CM_ "AUTOGENERATED FILE, DO NOT EDIT";

CM_ "Imported file _stellantis_common.dbc starts here";
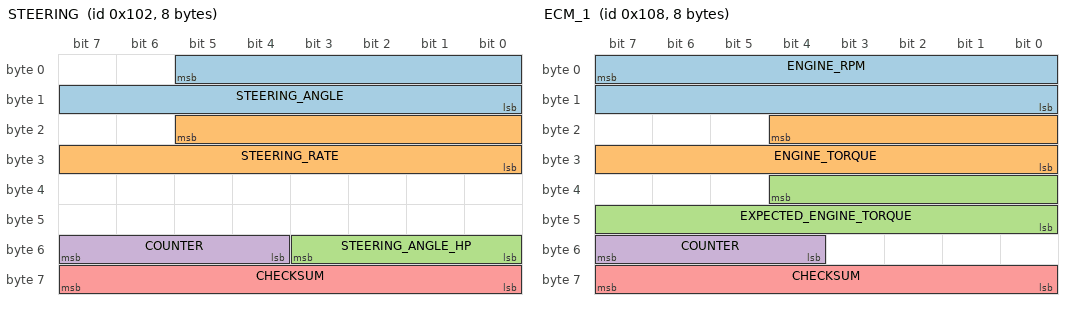
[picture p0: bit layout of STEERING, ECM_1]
BO_ 258 STEERING: 8 XXX
 SG_ STEERING_ANGLE : 5|14@0+ (0.5,-2048) [-2048|2047] "deg" XXX
 SG_ STEERING_RATE : 21|14@0+ (0.5,-2048) [-2048|2047] "deg/s" XXX
 SG_ STEERING_ANGLE_HP : 48|4@1+ (0.1,-0.4) [-0.4|0.4] "deg" XXX
 SG_ COUNTER : 55|4@0+ (1,0) [0|15] "" XXX
 SG_ CHECKSUM : 63|8@0+ (1,0) [0|255] "" XXX

BO_ 264 ECM_1: 8 XXX
 SG_ ENGINE_RPM : 7|16@0+ (1,0) [0|65535] "" XXX
 SG_ ENGINE_TORQUE : 20|13@0+ (0.25,-500) [-500|1547.5] "Nm" XXX
 SG_ EXPECTED_ENGINE_TORQUE : 36|13@0+ (0.25,-500) [-500|1547.5] "Nm" XXX
 SG_ COUNTER : 55|4@0+ (1,0) [0|15] "" XXX
 SG_ CHECKSUM : 63|8@0+ (1,0) [0|255] "" XXX

BO_ 280 ECM_TRQ: 8 XXX
 SG_ ENGINE_TORQ_MAX : 4|13@0+ (.25,-500) [-500|1547.5] "NM" XXX
 SG_ ENGINE_TORQ_MIN : 20|13@0+ (.25,-500) [-500|1547.5] "NM" XXX

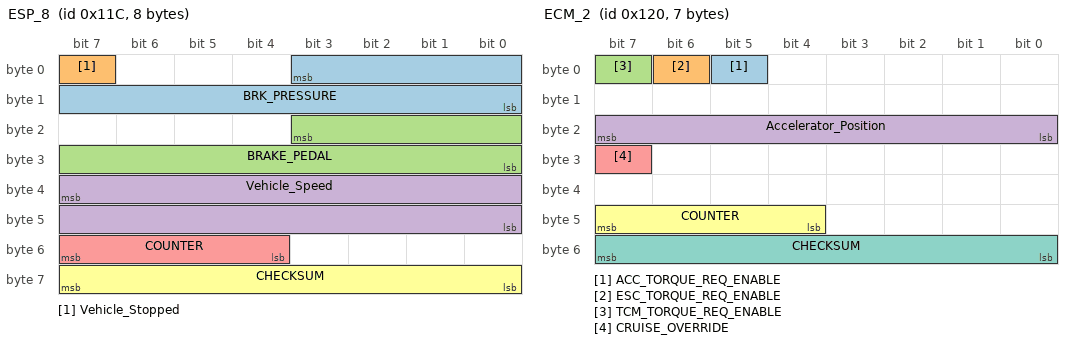
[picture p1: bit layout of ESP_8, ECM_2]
BO_ 284 ESP_8: 8 XXX
 SG_ BRK_PRESSURE : 3|12@0+ (1,0) [0|1] "" XXX
 SG_ Vehicle_Stopped : 7|1@0+ (1,0) [0|1] "" XXX
 SG_ BRAKE_PEDAL : 19|12@0+ (1,0) [0|1] "" XXX
 SG_ Vehicle_Speed : 39|16@0+ (0.0078125,0) [0|511.984375] "km/h" XXX
 SG_ COUNTER : 55|4@0+ (1,0) [0|15] "" XXX
 SG_ CHECKSUM : 63|8@0+ (1,0) [0|255] "" XXX

BO_ 288 ECM_2: 7 XXX
 SG_ ACC_TORQUE_REQ_ENABLE : 5|1@1+ (1,0) [0|0] "" XXX
 SG_ ESC_TORQUE_REQ_ENABLE : 6|1@1+ (1,0) [0|0] "" XXX
 SG_ TCM_TORQUE_REQ_ENABLE : 7|1@1+ (1,0) [0|0] "" XXX
 SG_ Accelerator_Position : 16|8@1+ (0.4,0) [0|100] "%" XXX
 SG_ CRUISE_OVERRIDE : 31|1@1+ (1,0) [0|0] "" XXX
 SG_ COUNTER : 47|4@0+ (1,0) [0|15] "" XXX
 SG_ CHECKSUM : 55|8@0+ (1,0) [0|0] "" XXX

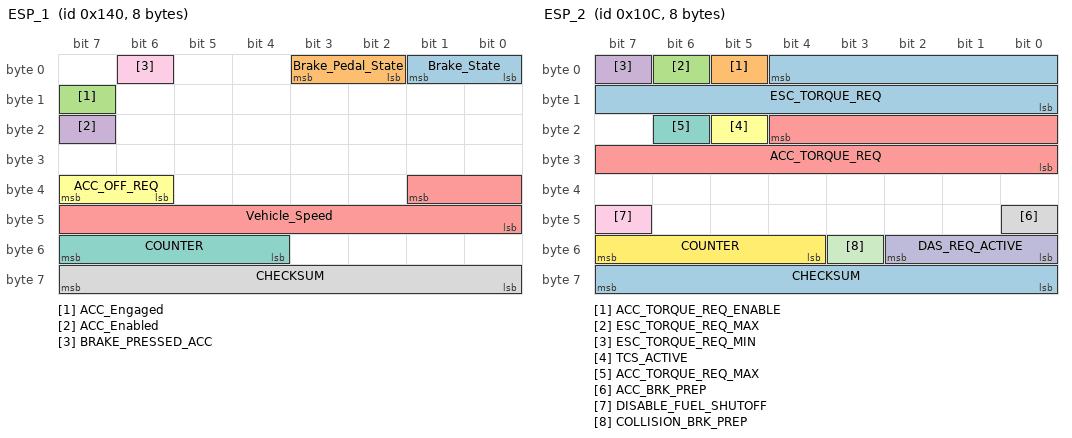
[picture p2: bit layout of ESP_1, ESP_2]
BO_ 320 ESP_1: 8 XXX
 SG_ Brake_State : 0|2@1+ (1,0) [0|0] "" XXX
 SG_ Brake_Pedal_State : 2|2@1+ (1,0) [0|0] "" XXX
 SG_ ACC_Engaged : 15|1@0+ (1,0) [0|1] "" XXX
 SG_ ACC_Enabled : 23|1@0+ (1,0) [0|1] "" XXX
 SG_ Vehicle_Speed : 33|10@0+ (0.5,0) [0|511] "km/h" XXX
 SG_ ACC_OFF_REQ : 39|2@0+ (1,0) [0|0] "" XXX
 SG_ COUNTER : 55|4@0+ (1,0) [0|15] "" XXX
 SG_ CHECKSUM : 63|8@0+ (1,0) [0|255] "" XXX
 SG_ BRAKE_PRESSED_ACC : 6|1@0+ (1,0) [0|3] "" XXX

BO_ 268 ESP_2: 8 ESC
 SG_ ESC_TORQUE_REQ : 4|13@0+ (0.25,-500) [-500|1547.5] "Nm" XXX
 SG_ ACC_TORQUE_REQ_ENABLE : 5|1@1+ (1,0) [0|0] "" XXX
 SG_ ESC_TORQUE_REQ_MAX : 6|1@1+ (1,0) [0|0] "" XXX
 SG_ ESC_TORQUE_REQ_MIN : 7|1@1+ (1,0) [0|0] "" XXX
 SG_ ACC_TORQUE_REQ : 20|13@0+ (0.25,-500) [-500|1547.5] "Nm" XXX
 SG_ TCS_ACTIVE : 21|1@1+ (1,0) [0|0] "" XXX
 SG_ ACC_TORQUE_REQ_MAX : 22|1@1+ (1,0) [0|0] "" XXX
 SG_ ACC_BRK_PREP : 40|1@1+ (1,0) [0|0] "" XXX
 SG_ DISABLE_FUEL_SHUTOFF : 47|1@1+ (1,0) [0|0] "" XXX
 SG_ DAS_REQ_ACTIVE : 48|3@1+ (1,0) [0|0] "" XXX
 SG_ COLLISION_BRK_PREP : 51|1@1+ (1,0) [0|0] "" XXX
 SG_ COUNTER : 55|4@0+ (1,0) [0|15] "" XXX
 SG_ CHECKSUM : 63|8@0+ (1,0) [0|0] "" XXX

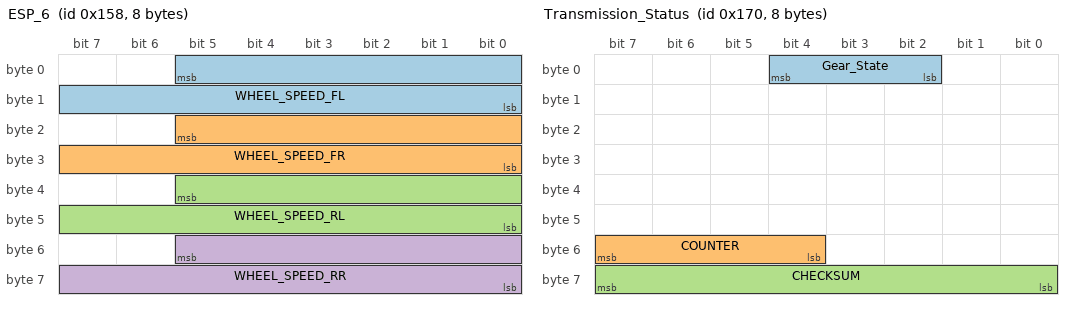
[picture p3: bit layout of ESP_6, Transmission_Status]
BO_ 344 ESP_6: 8 XXX
 SG_ WHEEL_SPEED_FL : 5|14@0+ (0.5,0) [0|8191] "rpm" XXX
 SG_ WHEEL_SPEED_FR : 21|14@0+ (0.5,0) [0|8191] "rpm" XXX
 SG_ WHEEL_SPEED_RL : 37|14@0+ (0.5,0) [0|8191] "rpm" XXX
 SG_ WHEEL_SPEED_RR : 53|14@0+ (0.5,0) [0|8191] "rpm" XXX

BO_ 368 Transmission_Status: 8 XXX
 SG_ Gear_State : 2|3@1+ (1,0) [0|15] "" XXX
 SG_ COUNTER : 55|4@0+ (1,0) [0|15] "" XXX
 SG_ CHECKSUM : 63|8@0+ (1,0) [0|255] "" XXX

BO_ 464 ORC_1: 8 XXX
 SG_ SEATBELT_DRIVER_UNLATCHED : 13|1@0+ (1,0) [0|1] "" XXX

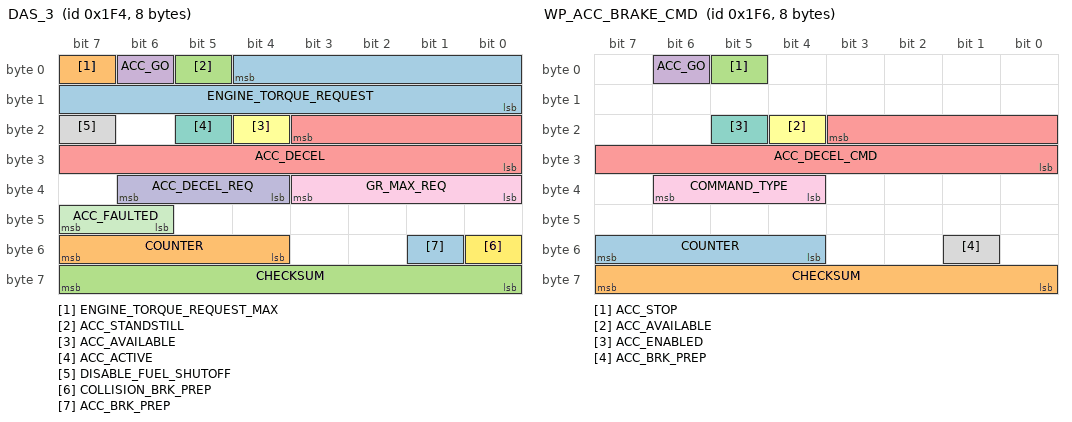
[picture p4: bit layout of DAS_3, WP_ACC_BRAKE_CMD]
BO_ 500 DAS_3: 8 XXX
 SG_ ENGINE_TORQUE_REQUEST : 4|13@0+ (0.25,-500) [-500|1547.5] "Nm" XXX
 SG_ ENGINE_TORQUE_REQUEST_MAX : 7|1@0+ (1,0) [0|1] "" XXX
 SG_ ACC_STANDSTILL : 5|1@0+ (1,0) [0|1] ""  XXX
 SG_ ACC_GO : 6|1@1+ (1,0) [0|0] "" XXX
 SG_ ACC_DECEL : 19|12@0+ (0.004885,-16) [-16|4] "m/s2" XXX
 SG_ ACC_AVAILABLE : 20|1@0+ (1,0) [0|1] "" XXX
 SG_ ACC_ACTIVE : 21|1@0+ (1,0) [0|1] "" XXX
 SG_ DISABLE_FUEL_SHUTOFF : 23|1@1+ (1,0) [0|0] "" XXX
 SG_ GR_MAX_REQ : 32|4@1+ (1,0) [0|0] "" XXX
 SG_ ACC_DECEL_REQ : 36|3@1+ (1,0) [0|0] "" XXX
 SG_ ACC_FAULTED : 46|2@1+ (1,0) [0|0] "" XXX
 SG_ COLLISION_BRK_PREP : 48|1@1+ (1,0) [0|0] "" XXX
 SG_ ACC_BRK_PREP : 49|1@1+ (1,0) [0|0] "" XXX
 SG_ COUNTER : 55|4@0+ (1,0) [0|15] "" XXX
 SG_ CHECKSUM : 63|8@0+ (1,0) [0|255] "" XXX

BO_ 502 WP_ACC_BRAKE_CMD: 8 XXX
 SG_ COUNTER : 55|4@0+ (1,0) [0|15] "" XXX
 SG_ CHECKSUM : 63|8@0+ (1,0) [0|255] "" XXX
 SG_ ACC_STOP : 5|1@0+ (1,0) [0|1] "" XXX
 SG_ ACC_GO : 6|1@0+ (1,0) [0|1] "" XXX
 SG_ ACC_DECEL_CMD : 19|12@0+ (0.004885,-16) [-16|4] "m/s2" XXX
 SG_ ACC_AVAILABLE : 20|1@0+ (1,0) [0|1] "" XXX
 SG_ ACC_ENABLED : 21|1@0+ (1,0) [0|1] "" XXX
 SG_ ACC_BRK_PREP : 49|1@0+ (1,0) [0|1] "" XXX
 SG_ COMMAND_TYPE : 38|3@0+ (1,0) [0|7] "" XXX

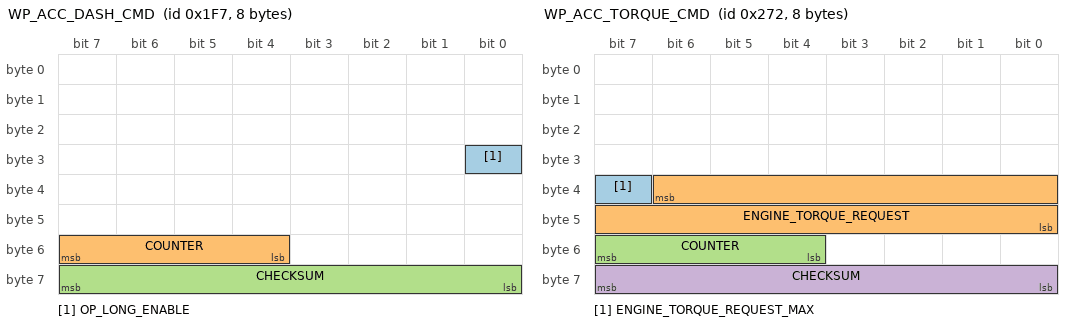
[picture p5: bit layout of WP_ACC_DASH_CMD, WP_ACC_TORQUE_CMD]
BO_ 503 WP_ACC_DASH_CMD: 8 XXX
 SG_ OP_LONG_ENABLE : 24|1@0+ (1,0) [0|1] "" XXX
 SG_ COUNTER : 55|4@0+ (1,0) [0|15] "" XXX
 SG_ CHECKSUM : 63|8@0+ (1,0) [0|255] "" XXX

BO_ 626 WP_ACC_TORQUE_CMD: 8 XXX
 SG_ ENGINE_TORQUE_REQUEST_MAX : 39|1@0+ (1,0) [0|1] "" XXX
 SG_ ENGINE_TORQUE_REQUEST : 38|15@0+ (0.25,-500) [-500|1547.5] "Nm" XXX
 SG_ COUNTER : 55|4@0+ (1,0) [0|15] "" XXX
 SG_ CHECKSUM : 63|8@0+ (1,0) [0|255] "" XXX

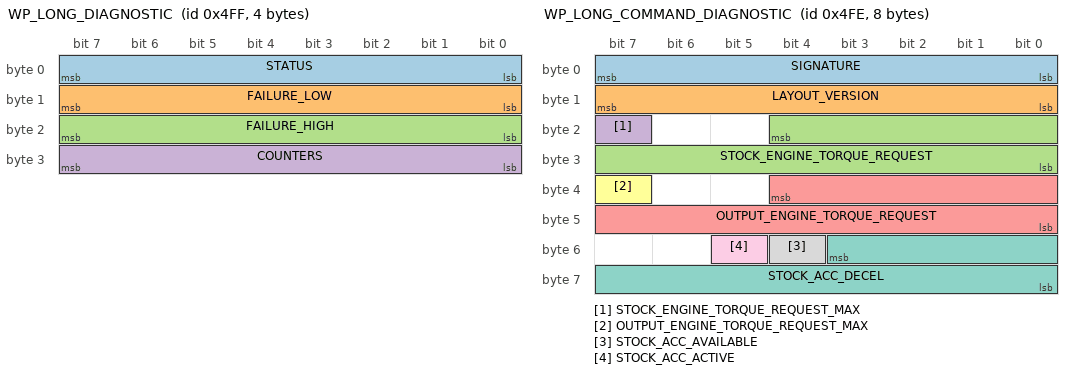
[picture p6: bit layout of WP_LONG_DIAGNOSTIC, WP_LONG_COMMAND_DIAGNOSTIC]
BO_ 1279 WP_LONG_DIAGNOSTIC: 4 XXX
 SG_ STATUS : 7|8@0+ (1,0) [0|255] "" XXX
 SG_ FAILURE_LOW : 15|8@0+ (1,0) [0|255] "" XXX
 SG_ FAILURE_HIGH : 23|8@0+ (1,0) [0|255] "" XXX
 SG_ COUNTERS : 31|8@0+ (1,0) [0|255] "" XXX

BO_ 1278 WP_LONG_COMMAND_DIAGNOSTIC: 8 XXX
 SG_ SIGNATURE : 7|8@0+ (1,0) [0|255] "" XXX
 SG_ LAYOUT_VERSION : 15|8@0+ (1,0) [0|255] "" XXX
 SG_ STOCK_ENGINE_TORQUE_REQUEST : 20|13@0+ (0.25,-500) [-500|1547.5] "Nm" XXX
 SG_ STOCK_ENGINE_TORQUE_REQUEST_MAX : 23|1@0+ (1,0) [0|1] "" XXX
 SG_ OUTPUT_ENGINE_TORQUE_REQUEST : 36|13@0+ (0.25,-500) [-500|1547.5] "Nm" XXX
 SG_ OUTPUT_ENGINE_TORQUE_REQUEST_MAX : 39|1@0+ (1,0) [0|1] "" XXX
 SG_ STOCK_ACC_DECEL : 51|12@0+ (0.004885,-16) [-16|4] "m/s2" XXX
 SG_ STOCK_ACC_AVAILABLE : 52|1@0+ (1,0) [0|1] "" XXX
 SG_ STOCK_ACC_ACTIVE : 53|1@0+ (1,0) [0|1] "" XXX

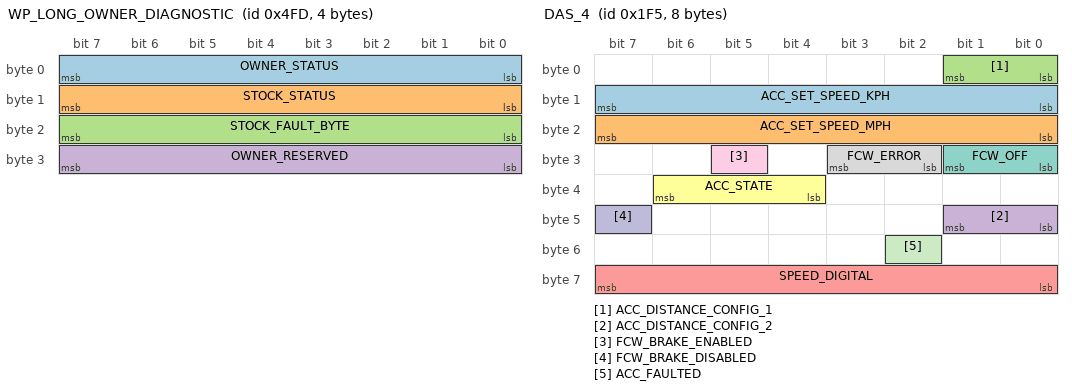
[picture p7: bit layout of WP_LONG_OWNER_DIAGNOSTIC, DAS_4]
BO_ 1277 WP_LONG_OWNER_DIAGNOSTIC: 4 XXX
 SG_ OWNER_STATUS : 7|8@0+ (1,0) [0|255] "" XXX
 SG_ STOCK_STATUS : 15|8@0+ (1,0) [0|255] "" XXX
 SG_ STOCK_FAULT_BYTE : 23|8@0+ (1,0) [0|255] "" XXX
 SG_ OWNER_RESERVED : 31|8@0+ (1,0) [0|255] "" XXX

BO_ 501 DAS_4: 8 XXX
 SG_ ACC_SET_SPEED_KPH : 15|8@0+ (1,0) [0|3] "km/h" XXX
 SG_ ACC_SET_SPEED_MPH : 23|8@0+ (1,0) [0|3] "mph" XXX
 SG_ ACC_DISTANCE_CONFIG_1 : 1|2@0+ (1,0) [0|3] "" XXX
 SG_ ACC_DISTANCE_CONFIG_2 : 41|2@0+ (1,0) [0|3] "" XXX
 SG_ SPEED_DIGITAL : 63|8@0+ (1,0) [0|255] "mph" XXX
 SG_ ACC_STATE : 38|3@0+ (1,0) [0|7] "" XXX
 SG_ FCW_OFF : 25|2@0+ (1,0) [0|3] "" XXX
 SG_ FCW_ERROR : 27|2@0+ (1,0) [0|3] "" XXX
 SG_ FCW_BRAKE_ENABLED : 29|1@0+ (1,0) [0|1] "" XXX
 SG_ FCW_BRAKE_DISABLED : 47|1@0+ (1,0) [0|1] "" XXX
 SG_ ACC_FAULTED : 50|1@0+ (1,0) [0|1] "" XXX

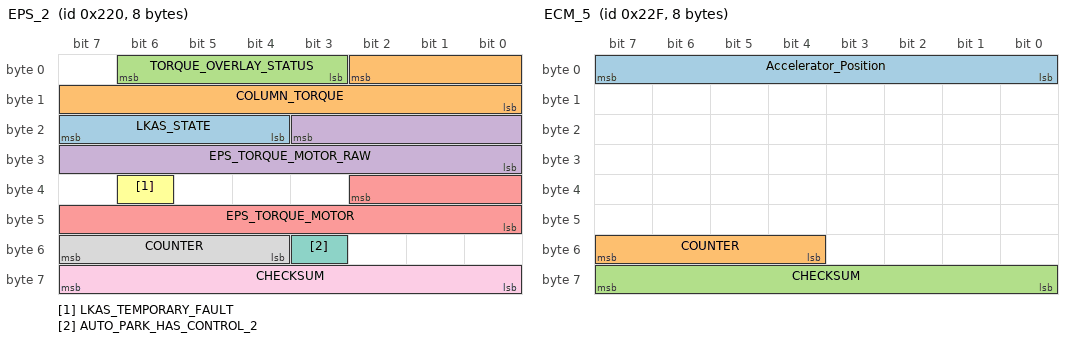
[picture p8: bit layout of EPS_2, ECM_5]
BO_ 544 EPS_2: 8 XXX
 SG_ LKAS_STATE : 23|4@0+ (1,0) [0|15] "" XXX
 SG_ COLUMN_TORQUE : 2|11@0+ (1,-1024) [-1024|1023] "" XXX
 SG_ TORQUE_OVERLAY_STATUS : 6|4@0+ (1,0) [0|15] "" XXX
 SG_ EPS_TORQUE_MOTOR_RAW : 19|12@0+ (1,-2048) [-2048|2047] "" XXX
 SG_ EPS_TORQUE_MOTOR : 34|11@0+ (1,-1024) [-1024|1023] "" XXX
 SG_ LKAS_TEMPORARY_FAULT : 38|1@0+ (1,0) [0|1] "" XXX
 SG_ AUTO_PARK_HAS_CONTROL_2 : 51|1@0+ (1,0) [0|1] "" XXX
 SG_ COUNTER : 55|4@0+ (1,0) [0|15] "" XXX
 SG_ CHECKSUM : 63|8@0+ (1,0) [0|255] "" XXX

BO_ 559 ECM_5: 8 XXX
 SG_ Accelerator_Position : 0|8@1+ (0.4,0) [0|100] "%" XXX
 SG_ COUNTER : 55|4@0+ (1,0) [0|15] "" XXX
 SG_ CHECKSUM : 63|8@0+ (1,0) [0|255] "" XXX

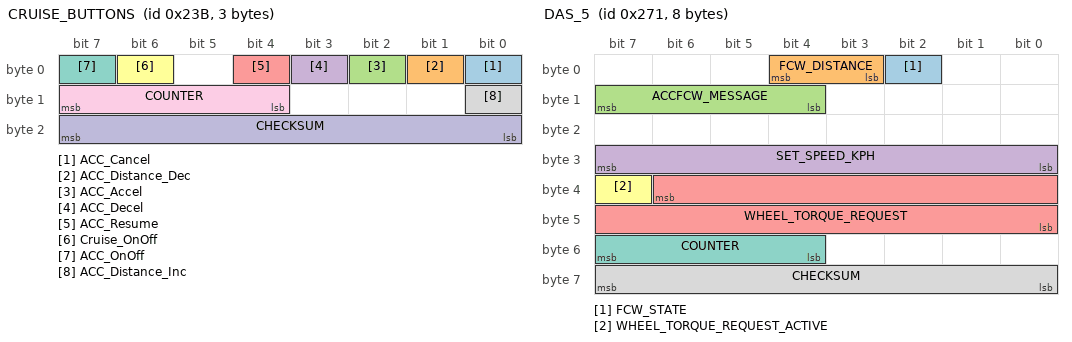
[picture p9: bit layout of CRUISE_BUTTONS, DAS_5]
BO_ 571 CRUISE_BUTTONS: 3 XXX
 SG_ ACC_Cancel : 0|1@1+ (1,0) [0|0] "" XXX
 SG_ ACC_Distance_Dec : 1|1@1+ (1,0) [0|0] "" XXX
 SG_ ACC_Accel : 2|1@1+ (1,0) [0|0] "" XXX
 SG_ ACC_Decel : 3|1@1+ (1,0) [0|0] "" XXX
 SG_ ACC_Resume : 4|1@0+ (1,0) [0|1] "" XXX
 SG_ Cruise_OnOff : 6|1@1+ (1,0) [0|0] "" XXX
 SG_ ACC_OnOff : 7|1@1+ (1,0) [0|0] "" XXX
 SG_ ACC_Distance_Inc : 8|1@1+ (1,0) [0|0] "" XXX
 SG_ COUNTER : 15|4@0+ (1,0) [0|15] "" XXX
 SG_ CHECKSUM : 23|8@0+ (1,0) [0|255] "" XXX

BO_ 625 DAS_5: 8 XXX
 SG_ FCW_STATE : 2|1@1+ (1,0) [0|0] ""  XXX
 SG_ FCW_DISTANCE : 3|2@1+ (1,0) [0|0] ""  XXX
 SG_ ACCFCW_MESSAGE : 12|4@1+ (1,0) [0|0] ""  XXX
 SG_ SET_SPEED_KPH : 24|8@1+ (1,0) [0|250] "km/h"  XXX
 SG_ WHEEL_TORQUE_REQUEST : 38|15@0+ (1,-7767) [-7767|24999] "Nm"  XXX
 SG_ WHEEL_TORQUE_REQUEST_ACTIVE : 39|1@1+ (1,0) [0|0] ""  XXX
 SG_ COUNTER : 55|4@0+ (1,0) [0|15] "" XXX
 SG_ CHECKSUM : 63|8@0+ (1,0) [0|255] "" XXX

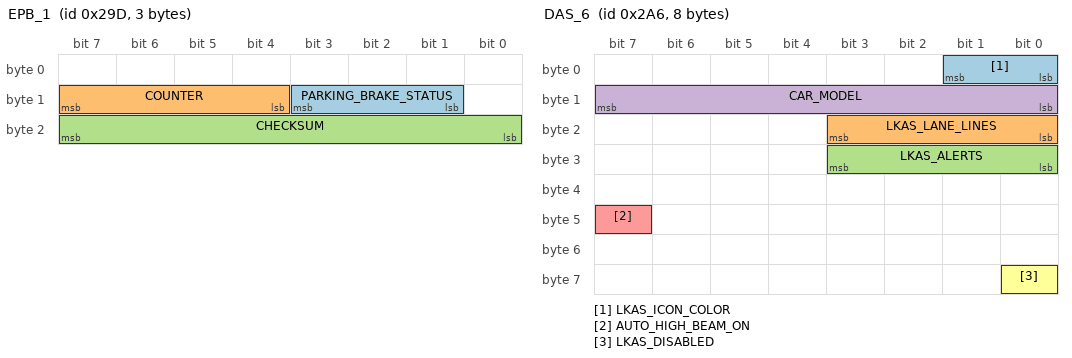
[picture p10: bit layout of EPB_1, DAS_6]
BO_ 669 EPB_1: 3 XXX
 SG_ PARKING_BRAKE_STATUS : 11|3@0+ (1,0) [0|7] "" XXX
 SG_ COUNTER : 15|4@0+ (1,0) [0|15] "" XXX
 SG_ CHECKSUM : 23|8@0+ (1,0) [0|255] "" XXX

BO_ 678 DAS_6: 8 XXX
 SG_ LKAS_ICON_COLOR : 1|2@0+ (1,0) [0|3] "" XXX
 SG_ LKAS_LANE_LINES : 19|4@0+ (1,0) [0|1] "" XXX
 SG_ LKAS_ALERTS : 27|4@0+ (1,0) [0|1] "" XXX
 SG_ CAR_MODEL : 15|8@0+ (1,0) [0|255] "" XXX
 SG_ AUTO_HIGH_BEAM_ON : 47|1@1+ (1,0) [0|0] "" XXX
 SG_ LKAS_DISABLED : 56|1@1+ (1,0) [0|0] "" XXX

BO_ 720 BSM_1: 6 XXX
 SG_ RIGHT_STATUS : 5|1@0+ (1,0) [0|1] "" XXX
 SG_ LEFT_STATUS : 2|1@0+ (1,0) [0|1] "" XXX

BO_ 792 STEERING_LEVERS: 8 XXX
 SG_ TURN_SIGNALS : 0|2@1+ (1,0) [0|3] "" XXX
 SG_ HIGH_BEAM_PRESSED : 2|1@0+ (1,0) [0|3] "" XXX

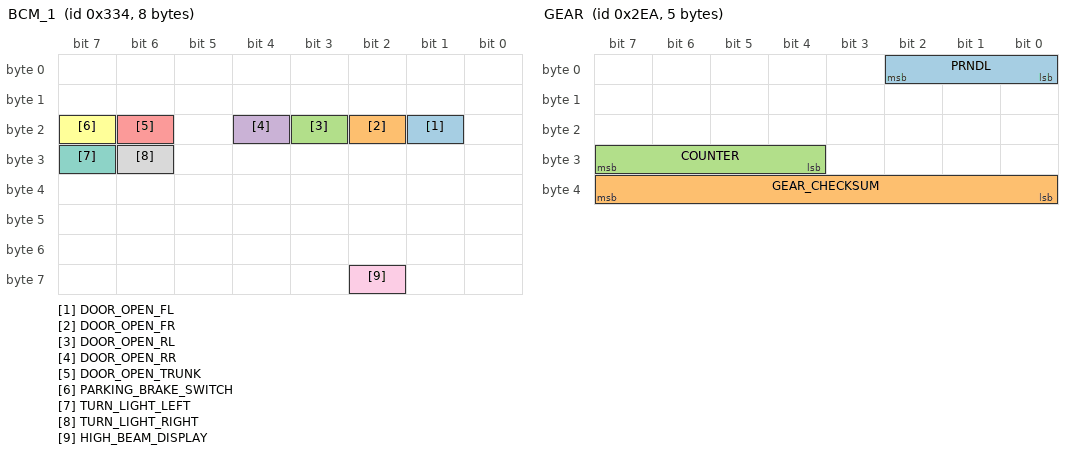
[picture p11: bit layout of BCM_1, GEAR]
BO_ 820 BCM_1: 8 XXX
 SG_ DOOR_OPEN_FL : 17|1@0+ (1,0) [0|1] "" XXX
 SG_ DOOR_OPEN_FR : 18|1@0+ (1,0) [0|1] "" XXX
 SG_ DOOR_OPEN_RL : 19|1@0+ (1,0) [0|1] "" XXX
 SG_ DOOR_OPEN_RR : 20|1@0+ (1,0) [0|1] "" XXX
 SG_ DOOR_OPEN_TRUNK : 22|1@0+ (1,0) [0|1] "" XXX
 SG_ PARKING_BRAKE_SWITCH : 23|1@0+ (1,0) [0|1] "" XXX
 SG_ TURN_LIGHT_LEFT : 31|1@0+ (1,0) [0|1] "" XXX
 SG_ TURN_LIGHT_RIGHT : 30|1@0+ (1,0) [0|1] "" XXX
 SG_ HIGH_BEAM_DISPLAY : 58|1@0+ (1,0) [0|1] "" XXX

VAL_ 320 ACC_OFF_REQ 2 "PERMANENT" 1 "TEMPORARY" 0 "NONE"
VAL_ 368 Gear_State 4 "D" 2 "N" 1 "R" 0 "P" ;
VAL_ 669 PARKING_BRAKE_STATUS 3 "RELEASING" 2 "APPLYING" 1 "APPLIED" 0 "OFF" ;

CM_ SG_ 258 STEERING_ANGLE_HP "Steering angle high precision";
CM_ SG_ 264 ENGINE_TORQUE "Effective engine torque";
CM_ SG_ 264 EXPECTED_ENGINE_TORQUE "Expected Engine Torque based on target engine speed";
CM_ SG_ 678 LKAS_ICON_COLOR "3 is yellow, 2 is green, 1 is white, 0 is null";
CM_ SG_ 678 LKAS_LANE_LINES "0x01 transparent lines, 0x02 left white, 0x03 right white, 0x04 left yellow with car on top, 0x05 left yellow with car on top, 0x06 both white, 0x07 left yellow, 0x08 left yellow right white, 0x09 right yellow, 0x0a right yellow left white, 0x0b left yellow with car on top right white, 0x0c right yellow with car on top left white, (0x00, 0x0d, 0x0e, 0x0f) null";
CM_ SG_ 678 LKAS_ALERTS "(0x01, 0x02) lane sense off, (0x03, 0x04, 0x06) place hands on steering wheel, 0x07 lane departure detected + place hands on steering wheel, (0x08, 0x09) lane sense unavailable + clean front windshield, 0x0b lane sense and auto high beam unavailable + clean front windshield, 0x0c lane sense unavailable + service required, (0x00, 0x05, 0x0a, 0x0d, 0x0e, 0x0f) null";

CM_ "chrysler_pacifica_2017_hybrid.dbc starts here";

BO_ 514 SPEED_1: 8 XXX
 SG_ SPEED_LEFT : 7|12@0+ (0.071028,0) [0|65535] "m/s" XXX
 SG_ SPEED_RIGHT : 23|12@0+ (0.071028,0) [0|1023] "m/s" XXX

BO_ 653 BRAKE_MODULE: 2 XXX
 SG_ BRAKE_PRESSURE : 15|8@0+ (1,0) [0|255] "" XXX
 SG_ BRAKE_PRESSED : 4|1@0+ (1,0) [0|4] "" XXX

BO_ 746 GEAR: 5 XXX
 SG_ PRNDL : 2|3@0+ (1,0) [0|7] "" XXX
 SG_ GEAR_CHECKSUM : 39|8@0+ (1,0) [0|255] "" XXX
 SG_ COUNTER : 31|4@0+ (1,0) [0|15] "" XXX

BO_ 736 TRIP: 8 XXX
 SG_ COUNTER : 7|16@0+ (1,0) [0|65535] "Meters" XXX
 SG_ COUNTER_2 : 23|16@0+ (1,0) [0|65535] "Meters" XXX

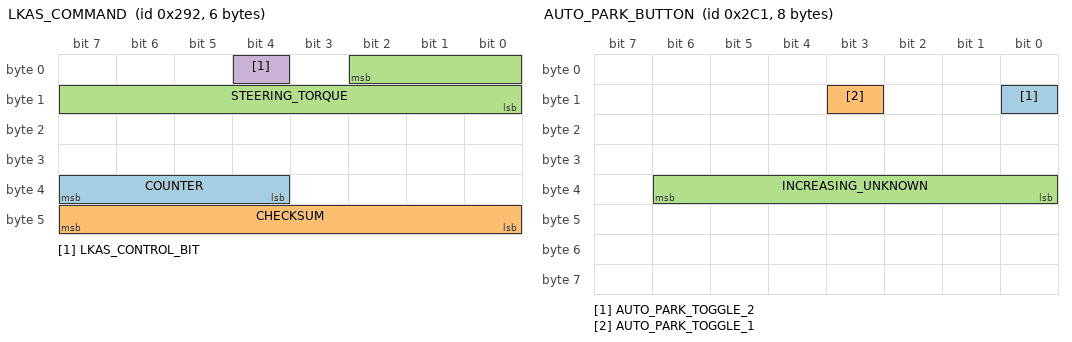
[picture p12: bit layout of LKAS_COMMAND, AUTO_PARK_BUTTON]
BO_ 658 LKAS_COMMAND: 6 XXX
 SG_ COUNTER : 39|4@0+ (1,0) [0|15] "" XXX
 SG_ CHECKSUM : 47|8@0+ (1,0) [0|255] "" XXX
 SG_ STEERING_TORQUE : 2|11@0+ (1,-1024) [0|1] "" XXX
 SG_ LKAS_CONTROL_BIT : 4|1@0+ (1,0) [0|1] "" XXX

BO_ 705 AUTO_PARK_BUTTON: 8 XXX
 SG_ AUTO_PARK_TOGGLE_2 : 8|1@0+ (1,0) [0|1] "" XXX
 SG_ AUTO_PARK_TOGGLE_1 : 11|1@0+ (1,0) [0|1] "" XXX
 SG_ INCREASING_UNKNOWN : 38|7@0+ (1,0) [0|15] "" XXX

BO_ 719 AUTO_PARK_SIGNALS_1: 8 XXX
 SG_ AUTO_PARK_UNKNOWN_1 : 7|16@0+ (1,0) [0|31] "" XXX

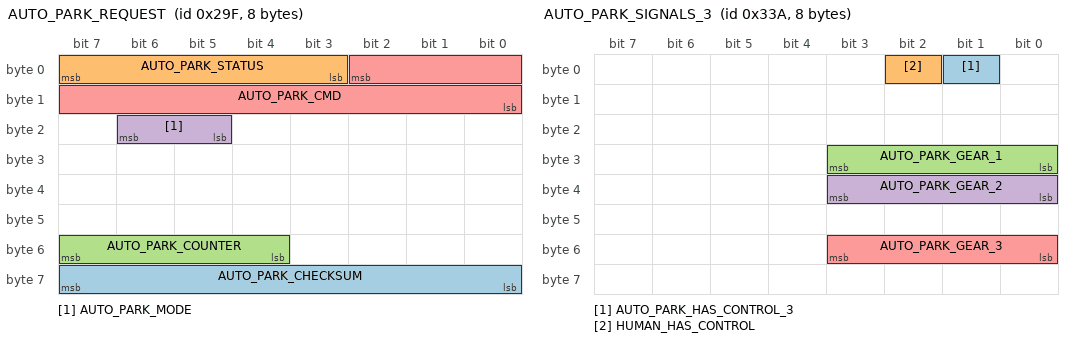
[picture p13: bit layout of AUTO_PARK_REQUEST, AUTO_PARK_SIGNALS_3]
BO_ 671 AUTO_PARK_REQUEST: 8 XXX
 SG_ AUTO_PARK_CHECKSUM : 63|8@0+ (1,0) [0|255] "" XXX
 SG_ AUTO_PARK_STATUS : 7|5@0+ (1,0) [0|15] "" XXX
 SG_ AUTO_PARK_COUNTER : 55|4@0+ (1,0) [0|15] "" XXX
 SG_ AUTO_PARK_MODE : 22|2@0+ (1,0) [0|3] "" XXX
 SG_ AUTO_PARK_CMD : 2|11@0+ (1,-1024) [0|1] "NM" XXX

BO_ 784 AUTO_PARK_LESS_INTERESTING: 8 XXX
 SG_ INCREASING_UNKNOWN : 55|8@0+ (1,0) [0|7] "" XXX
 SG_ AUTO_PARK_PERPENDICULAR_2 : 61|1@0+ (1,0) [0|255] "" XXX

BO_ 826 AUTO_PARK_SIGNALS_3: 8 XXX
 SG_ AUTO_PARK_HAS_CONTROL_3 : 1|1@0+ (1,0) [0|1] "" XXX
 SG_ HUMAN_HAS_CONTROL : 2|1@0+ (1,0) [0|1] "" XXX
 SG_ AUTO_PARK_GEAR_1 : 27|4@0+ (1,0) [0|255] "" XXX
 SG_ AUTO_PARK_GEAR_2 : 35|4@0+ (1,0) [0|15] "" XXX
 SG_ AUTO_PARK_GEAR_3 : 51|4@0+ (1,0) [0|15] "" XXX

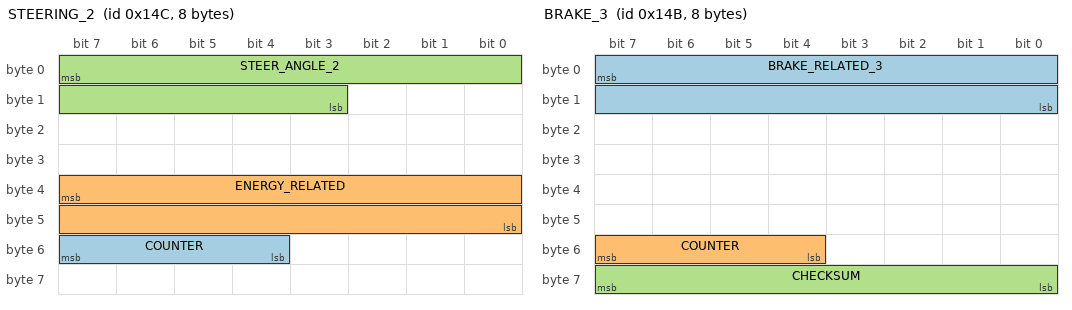
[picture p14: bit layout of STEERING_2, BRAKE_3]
BO_ 332 STEERING_2: 8 XXX
 SG_ COUNTER : 55|4@0+ (1,0) [0|15] "" XXX
 SG_ ENERGY_RELATED : 39|16@0+ (1,0) [0|65535] "" XXX
 SG_ STEER_ANGLE_2 : 7|13@0+ (0.3187251,-1307.888) [-360|360] "deg" XXX

BO_ 331 BRAKE_3: 8 XXX
 SG_ BRAKE_RELATED_3 : 7|16@0+ (1,0) [0|65535] "" XXX
 SG_ COUNTER : 55|4@0+ (1,0) [0|15] "" XXX
 SG_ CHECKSUM : 63|8@0+ (1,0) [0|255] "" XXX

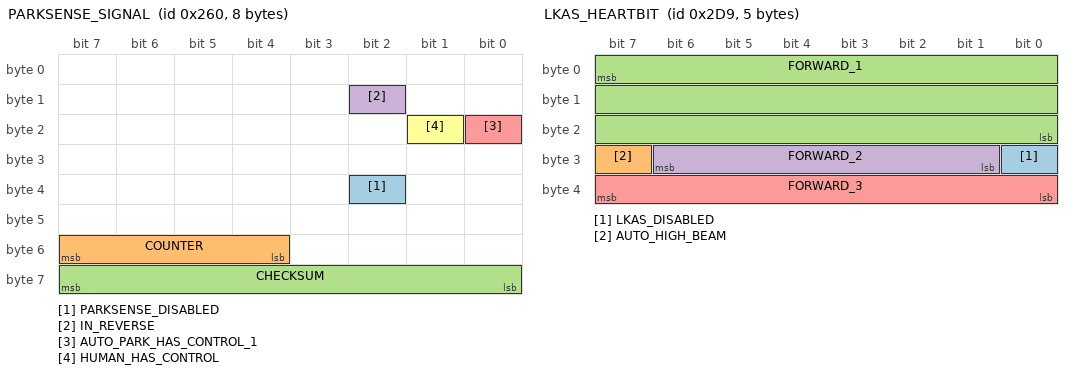
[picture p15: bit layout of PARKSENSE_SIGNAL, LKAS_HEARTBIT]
BO_ 608 PARKSENSE_SIGNAL: 8 XXX
 SG_ PARKSENSE_DISABLED : 34|1@0+ (1,0) [0|1] "" XXX
 SG_ COUNTER : 55|4@0+ (1,0) [0|15] "" XXX
 SG_ CHECKSUM : 63|8@0+ (1,0) [0|255] "" XXX
 SG_ IN_REVERSE : 10|1@0+ (1,0) [0|255] "" XXX
 SG_ AUTO_PARK_HAS_CONTROL_1 : 16|1@0+ (1,0) [0|255] "" XXX
 SG_ HUMAN_HAS_CONTROL : 17|1@0+ (1,0) [0|3] "" XXX

BO_ 729 LKAS_HEARTBIT: 5 XXX
 SG_ LKAS_DISABLED : 24|1@0+ (1,0) [0|1] "" XXX
 SG_ AUTO_HIGH_BEAM : 31|1@0+ (1,0) [0|1] "" XXX
 SG_ FORWARD_1 : 7|24@0+ (1,0) [0|255] "" XXX
 SG_ FORWARD_2 : 30|6@0+ (1,0) [0|127] "" XXX
 SG_ FORWARD_3 : 39|8@0+ (1,0) [0|255] "" XXX

BO_ 257 ACCEL_RELATED_101: 5 XXX
 SG_ ENERGY_OR_RPM : 31|8@0+ (1,0) [0|255] "" XXX

BO_ 825 AUDIBLE_BEEP_339: 2 XXX
 SG_ BEEP_339 : 7|16@0+ (1,0) [0|65535] "" XXX

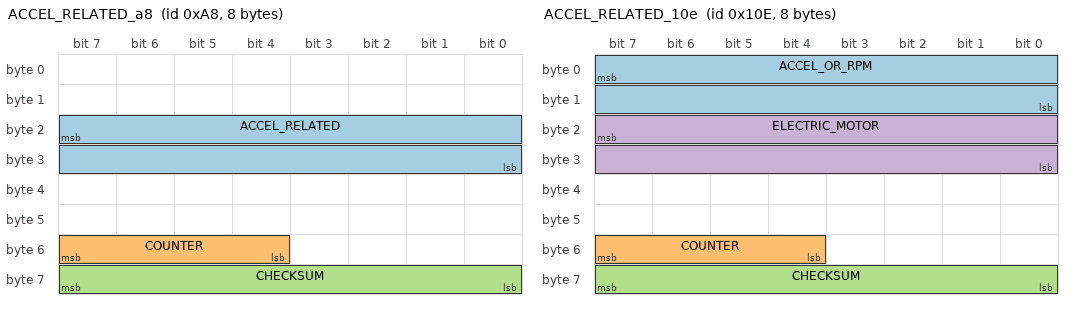
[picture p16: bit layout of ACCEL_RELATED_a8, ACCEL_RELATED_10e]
BO_ 168 ACCEL_RELATED_a8: 8 XXX
 SG_ ACCEL_RELATED : 23|16@0+ (1,0) [0|65535] "" XXX
 SG_ COUNTER : 55|4@0+ (1,0) [0|15] "" XXX
 SG_ CHECKSUM : 63|8@0+ (1,0) [0|255] "" XXX

BO_ 270 ACCEL_RELATED_10e: 8 XXX
 SG_ ACCEL_OR_RPM : 7|16@0+ (1,0) [0|255] "" XXX
 SG_ COUNTER : 55|4@0+ (1,0) [0|15] "" XXX
 SG_ CHECKSUM : 63|8@0+ (1,0) [0|255] "" XXX
 SG_ ELECTRIC_MOTOR : 23|16@0+ (1,0) [0|65535] "" XXX

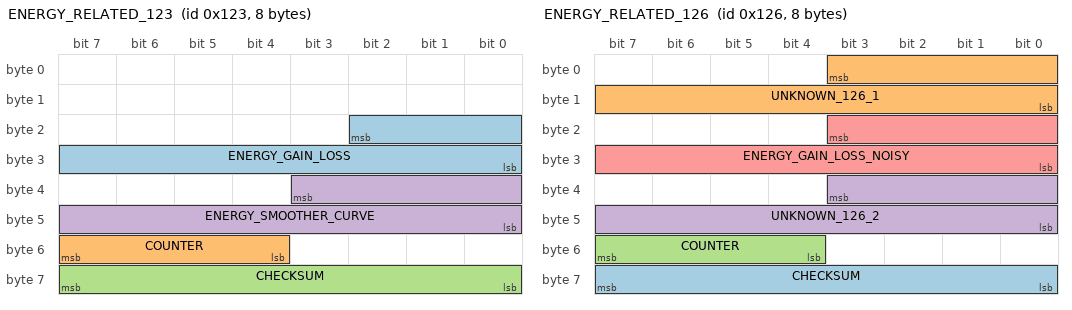
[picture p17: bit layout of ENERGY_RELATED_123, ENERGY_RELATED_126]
BO_ 291 ENERGY_RELATED_123: 8 XXX
 SG_ ENERGY_GAIN_LOSS : 18|11@0- (1,0) [0|255] "" XXX
 SG_ COUNTER : 55|4@0+ (1,0) [0|15] "" XXX
 SG_ CHECKSUM : 63|8@0+ (1,0) [0|255] "" XXX
 SG_ ENERGY_SMOOTHER_CURVE : 35|12@0+ (1,0) [0|2047] "" XXX

BO_ 294 ENERGY_RELATED_126: 8 XXX
 SG_ CHECKSUM : 63|8@0+ (1,0) [0|255] "" XXX
 SG_ UNKNOWN_126_1 : 3|12@0+ (1,0) [0|4095] "" XXX
 SG_ COUNTER : 55|4@0+ (1,0) [0|15] "" XXX
 SG_ UNKNOWN_126_2 : 35|12@0+ (1,0) [0|4095] "" XXX
 SG_ ENERGY_GAIN_LOSS_NOISY : 19|12@0+ (1,0) [0|2047] "" XXX

BO_ 308 ACCEL_GAS_134: 8 XXX
 SG_ COUNTER : 55|4@0+ (1,0) [0|15] "" XXX
 SG_ ACCEL_134 : 46|7@0+ (1,0) [0|127] "" XXX

BO_ 532 ENERGY_RELATED_214: 8 XXX
 SG_ NOISY_SLOWLY_DECREASING : 16|9@0+ (1,0) [0|255] "" XXX
 SG_ ENERGY_RELATED : 0|9@0+ (1,0) [0|255] "" XXX

BO_ 655 CHARGING_MAYBE_28F: 8 XXX
 SG_ CHARGING : 1|2@0+ (1,0) [0|3] "" XXX

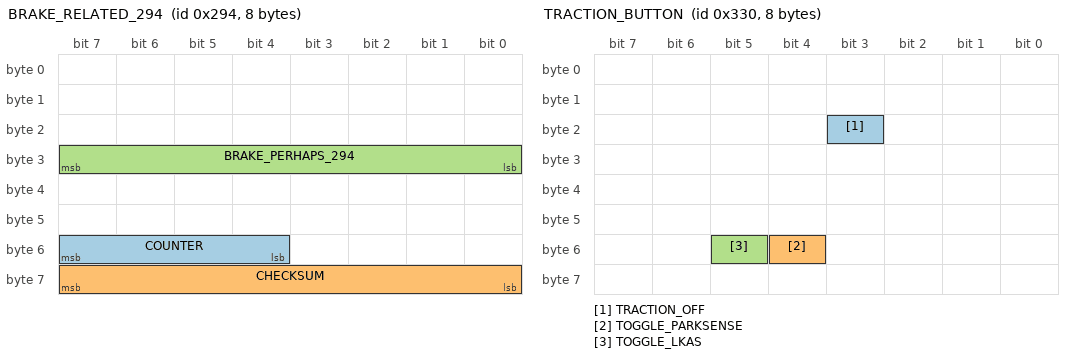
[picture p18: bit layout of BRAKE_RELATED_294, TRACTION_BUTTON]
BO_ 660 BRAKE_RELATED_294: 8 XXX
 SG_ COUNTER : 55|4@0+ (1,0) [0|15] "" XXX
 SG_ CHECKSUM : 63|8@0+ (1,0) [0|255] "" XXX
 SG_ BRAKE_PERHAPS_294 : 31|8@0+ (1,0) [0|255] "" XXX

BO_ 764 ACCEL_RELATED_2FC: 8 XXX
 SG_ ACCEL_2FC : 13|6@0+ (1,0) [0|255] "" XXX

BO_ 816 TRACTION_BUTTON: 8 XXX
 SG_ TRACTION_OFF : 19|1@0+ (1,0) [0|3] "" XXX
 SG_ TOGGLE_PARKSENSE : 52|1@0+ (1,0) [0|3] "" XXX
 SG_ TOGGLE_LKAS : 53|1@0+ (1,0) [0|1] "" XXX

BO_ 878 ACCEL_RELATED_36E: 8 XXX
 SG_ ACCEL_OR_RPM_2 : 15|8@0+ (1,0) [0|255] "" XXX
 SG_ ACCEL_OR_RPM_1 : 7|8@0+ (1,0) [0|255] "" XXX

BO_ 324 SPEED_2: 8 XXX
 SG_ SPEED_2 : 31|16@0+ (0.01,0) [0|255] "m/s" XXX

BO_ 832 UNKNOWN_340: 8 XXX
 SG_ SPEED_DIGITAL : 63|8@0+ (1,0) [0|255] "mph" XXX

CM_ SG_ 653 BRAKE_PRESSURE "max seems to be 148";
CM_ SG_ 746 PRNDL "5=L, 4=D, 3=N, 2=R, 1=P";
CM_ SG_ 320 BRAKE_PRESSED_2 "Value is 5 when brake is pressed by human, 1 when ACC brake";
CM_ SG_ 320 BRAKE_PRESSED_ACC "set when ACC brakes";
CM_ SG_ 792 TURN_SIGNALS "1=Left, 2=Right";
CM_ SG_ 264 ACCEL_PEDAL "not in ACC so seems to be actual pedal. Use for gasPressed";
CM_ SG_ 544 LKAS_STATE "2 when autopark has control, 8 when is actuatable by lkas, 4 when there is a fault";
CM_ SG_ 658 LKAS_STEERING_TORQUE "Most sent by stock system is 1024+-230. + is left. typically changes by 2 or 3 each 0.01s";
CM_ SG_ 678 LKAS_ICON_COLOR "3 is yellow, 2 is green, 1 is white, 0 is null";
CM_ SG_ 678 LKAS_LANE_LINES "0x01 transparent lines, 0x02 left white, 0x03 right white, 0x04 left yellow with car on top, 0x05 left yellow with car on top, 0x06 both white, 0x07 left yellow, 0x08 left yellow right white, 0x09 right yellow, 0x0a right yellow left white, 0x0b left yellow with car on top right white, 0x0c right yellow with car on top left white, (0x00, 0x0d, 0x0e, 0x0f) null";
CM_ SG_ 678 LKAS_ALERTS "(0x01, 0x02) lane sense off, (0x03, 0x04, 0x06) place hands on steering wheel, 0x07 lane departure detected + place hands on steering wheel, (0x08, 0x09) lane sense unavailable + clean front windshield, 0x0b lane sense and auto high beam unavailable + clean front windshield, 0x0c lane sense unavailable + service required, (0x00, 0x05, 0x0a, 0x0d, 0x0e, 0x0f) null";
CM_ SG_ 705 AUTO_PARK_TOGGLE_1 "set briefly when turning on or off self-parking";
CM_ SG_ 671 AUTO_PARK_CMD "Request Appears to be in NM";
CM_ SG_ 671 AUTO_PARK_STATUS "1 = IDLE / NO REQUEST 9 = START REQUEST 10 = REQUEST MODE 11 = REQUEST MODE";
CM_ SG_ 826 AUTO_PARK_GEAR_1 "Reverse=0, Forward=f";
CM_ SG_ 826 AUTO_PARK_GEAR_2 "Reverse=0, Forward=f";
CM_ SG_ 826 AUTO_PARK_GEAR_3 "Reverse=0, Forward=f";
CM_ SG_ 332 STEER_ANGLE_2 "slightly lags the other steer_angle signal. also more noisy.";
CM_ SG_ 608 PARKSENSE_DISABLED "set if parksense is disabled";
CM_ SG_ 729 LKAS_STATUS_OK "Set to 0x0820 when LKAS system is plugged in.";
CM_ SG_ 825 BEEP_339 "sent every 0.5s. 0050 is no beep. To beep send 4355 or 4155. Used by ParkSense warning.";
CM_ SG_ 270 ELECTRIC_MOTOR "0x7fff indicates electric motor not in use";
CM_ SG_ 291 ENERGY_GAIN_LOSS "unsure what this actually is";
CM_ SG_ 291 ENERGY_SMOOTHER_CURVE "unsure what it is, but smoother";
CM_ SG_ 308 ACCEL_134 "only set when human presses accel pedal";
CM_ SG_ 532 NOISY_SLOWLY_DECREASING "perhaps battery but do not know";
CM_ SG_ 816 TRACTION_OFF "set when traction off button is enabled";
CM_ SG_ 816 TOGGLE_PARKSENSE "sending 3000071ec0ff9000 enables or disables parksense";
CM_ SG_ 324 SPEED_2 "signal is approx half other speeds";
CM_ SG_ 501 ACC_SPEED_CONFIG_KPH "speed configured for ACC";
CM_ SG_ 501 ACC_SPEED_CONFIG_MPH "speed configured for ACC";
CM_ SG_ 501 CRUISE_STATE "may just be an icon, but seems to indicate different cruise modes: ACC and Non-ACC and engaged state for both.";
CM_ SG_ 625 SPEED "zero on non-acc drives";

VAL_ 501 CRUISE_STATE 0 "Off" 1 "CC On" 2 "CC Engaged" 3 "ACC On" 4 "ACC Engaged";
VAL_ 746 PRNDL 5 "L" 4 "D" 3 "N" 2 "R" 1 "P";
VAL_ 792 TURN_SIGNALS 2 "Right" 1 "Left";
